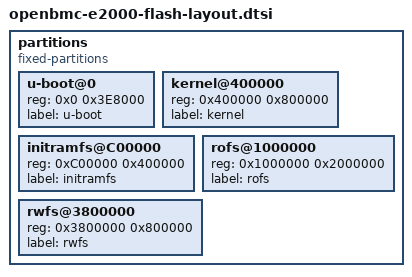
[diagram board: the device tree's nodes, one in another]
partitions {
        compatible = "fixed-partitions";
        #address-cells = <1>;
        #size-cells = <1>;

        u-boot@0 {
                reg = <0x0 0x3E8000>;
                label = "u-boot";
        };

        kernel@400000 {
                reg = <0x400000 0x800000>;
                label = "kernel";
        };

        initramfs@C00000 {
                reg = <0xC00000 0x400000>;
                label = "initramfs";
	};

        rofs@1000000 {
                reg = <0x1000000 0x2000000>;
                label = "rofs";
        };

        rwfs@3800000 {
                reg = <0x3800000 0x800000>;
                label = "rwfs";
        };
};

